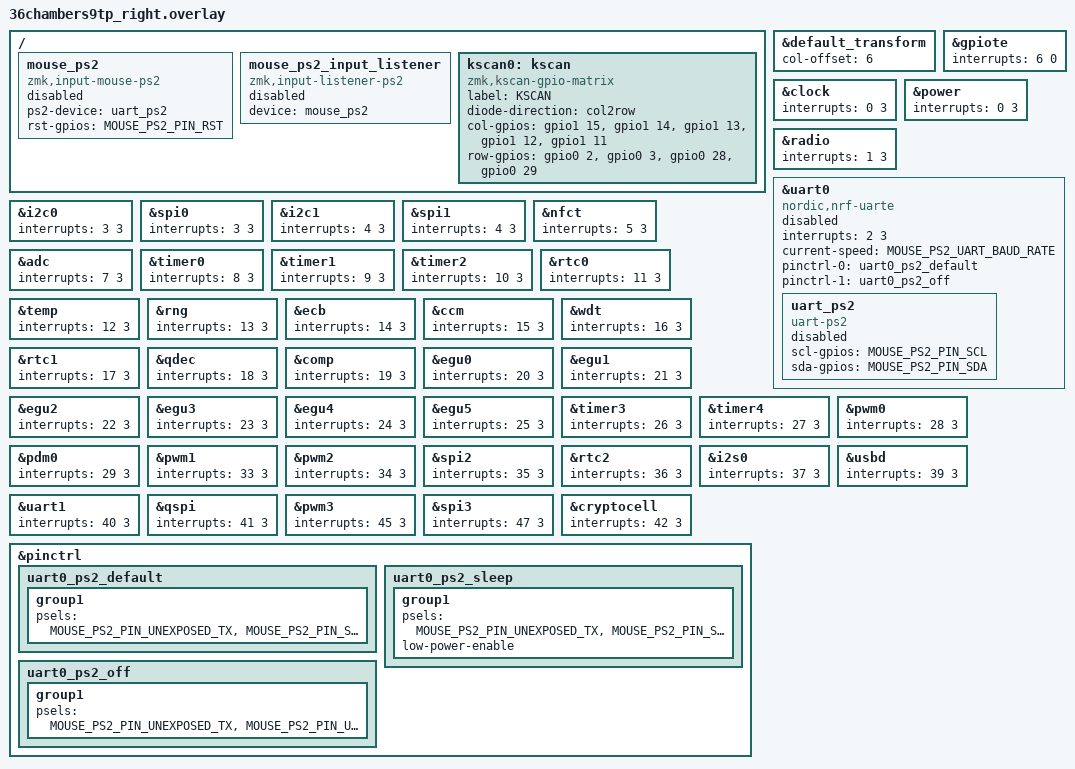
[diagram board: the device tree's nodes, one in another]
#include "36chambers9tp.dtsi"
#include <dt-bindings/zmk/input_transform.h>
#include <input/processors.dtsi>
/*
 * Pin Reference (XIAO BLE Plus):
 * SDA D4:  P0.04   SCL D5:  P1.11   DR D13:  P1.01
 * SS  D16: P0.31   MOSI D19: P1.07  MISO D18: P1.05  SCK D17: P1.03
 * Encoder Right1: P0.09 (D14), P0.10 (D15) — repurposed for trackpoint
 * Encoder Right2: P0.15 (D11), P0.19 (D12) — available
 *
 * PS/2 TrackPoint UART pin assignments:
 *   SDA (data / UART RX): P0.04
 *   SCL (clock / GPIO):   P0.09
 *   RST (reset / GPIO):   P0.10
 *   Dummy UART TX:         P0.27 (internal, not exposed)
 *   Dummy UART RX (off):   P1.01 (unused back pad)
 */

&default_transform {
	col-offset = <6>;
};

/*
 * PS/2 TrackPoint via UART — Configuration
 */
#define MOUSE_PS2_DRIVER_UART

#define MOUSE_PS2_PIN_SCL <&gpio0 9 GPIO_ACTIVE_HIGH>
#define MOUSE_PS2_PIN_SDA <&gpio0 4 GPIO_ACTIVE_HIGH>
#define MOUSE_PS2_PIN_SDA_PINCTRL <NRF_PSEL(UART_RX, 0, 4)>
#define MOUSE_PS2_PIN_RST <&gpio0 10 GPIO_ACTIVE_HIGH>

#define MOUSE_PS2_UART_BAUD_RATE <14400>

#define MOUSE_PS2_PIN_UNEXPOSED_TX <NRF_PSEL(UART_TX, 0, 27)>
#define MOUSE_PS2_PIN_UNEXPOSED_RX <NRF_PSEL(UART_RX, 1, 1)>

/*
 * Interrupt priority overrides — gpiote at highest (0), all others demoted to 3
 */
&gpiote { interrupts = < 6 0 >; };
&clock { interrupts = < 0 3 >; };
&power { interrupts = < 0 3 >; };
&radio { interrupts = < 1 3 >; };
&uart0 { interrupts = < 2 3 >; };
&i2c0 { interrupts = < 3 3 >; };
&spi0 { interrupts = < 3 3 >; };
&i2c1 { interrupts = < 4 3 >; };
&spi1 { interrupts = < 4 3 >; };
&nfct { interrupts = < 5 3 >; };
&adc { interrupts = < 7 3 >; };
&timer0 { interrupts = < 8 3 >; };
&timer1 { interrupts = < 9 3 >; };
&timer2 { interrupts = < 10 3 >; };
&rtc0 { interrupts = < 11 3 >; };
&temp { interrupts = < 12 3 >; };
&rng { interrupts = < 13 3 >; };
&ecb { interrupts = < 14 3 >; };
&ccm { interrupts = < 15 3 >; };
&wdt { interrupts = < 16 3 >; };
&rtc1 { interrupts = < 17 3 >; };
&qdec { interrupts = < 18 3 >; };
&comp { interrupts = < 19 3 >; };
&egu0 { interrupts = < 20 3 >; };
&egu1 { interrupts = < 21 3 >; };
&egu2 { interrupts = < 22 3 >; };
&egu3 { interrupts = < 23 3 >; };
&egu4 { interrupts = < 24 3 >; };
&egu5 { interrupts = < 25 3 >; };
&timer3 { interrupts = < 26 3 >; };
&timer4 { interrupts = < 27 3 >; };
&pwm0 { interrupts = < 28 3 >; };
&pdm0 { interrupts = < 29 3 >; };
&pwm1 { interrupts = < 33 3 >; };
&pwm2 { interrupts = < 34 3 >; };
&spi2 { interrupts = < 35 3 >; };
&rtc2 { interrupts = < 36 3 >; };
&i2s0 { interrupts = < 37 3 >; };
&usbd { interrupts = < 39 3 >; };
&uart1 { interrupts = < 40 3 >; };
&qspi { interrupts = < 41 3 >; };
&pwm3 { interrupts = < 45 3 >; };
&spi3 { interrupts = < 47 3 >; };
&cryptocell { interrupts = < 42 3 >; };

/*
 * Pinctrl — UART0 states for PS/2
 */
&pinctrl {
	uart0_ps2_default: uart0_ps2_default {
		group1 {
			psels = MOUSE_PS2_PIN_UNEXPOSED_TX,
					MOUSE_PS2_PIN_SDA_PINCTRL;
		};
	};
	uart0_ps2_sleep: uart0_ps2_sleep {
		group1 {
			psels = MOUSE_PS2_PIN_UNEXPOSED_TX,
					MOUSE_PS2_PIN_SDA_PINCTRL;
			low-power-enable;
		};
	};
	uart0_ps2_off: uart0_ps2_off {
		group1 {
			psels = MOUSE_PS2_PIN_UNEXPOSED_TX,
					MOUSE_PS2_PIN_UNEXPOSED_RX;
		};
	};
};

/*
 * UART0 — reconfigured for PS/2
 */
&uart0 {
    status = "disabled";
    compatible = "nordic,nrf-uarte";
    current-speed = MOUSE_PS2_UART_BAUD_RATE;
    pinctrl-0 = <&uart0_ps2_default>;
    pinctrl-1 = <&uart0_ps2_off>;
    pinctrl-names = "default", "sleep";

    uart_ps2: uart_ps2 {
        status = "disabled";
        compatible = "uart-ps2";
        scl-gpios = MOUSE_PS2_PIN_SCL;
        sda-gpios = MOUSE_PS2_PIN_SDA;
    };
};

/*
 * PS/2 Mouse input device and listener
 */
/ {
    mouse_ps2: mouse_ps2 {
        status = "disabled";
        compatible = "zmk,input-mouse-ps2";
        ps2-device = <&uart_ps2>;
        rst-gpios = MOUSE_PS2_PIN_RST;
    };

    mouse_ps2_input_listener: mouse_ps2_input_listener {
        compatible = "zmk,input-listener-ps2";
        status = "disabled";
        device = <&mouse_ps2>;
    };
};

/*
 * Keyboard matrix (right half)
 */
/ {
    kscan0: kscan {
        compatible = "zmk,kscan-gpio-matrix";
        label = "KSCAN";
        diode-direction = "col2row";
    col-gpios
    	= <&gpio1 15 GPIO_ACTIVE_HIGH>//Col0
        , <&gpio1 14 GPIO_ACTIVE_HIGH>//Col1
        , <&gpio1 13 GPIO_ACTIVE_HIGH>//Col2
        , <&gpio1 12 GPIO_ACTIVE_HIGH>//Col3
        , <&gpio1 11 GPIO_ACTIVE_HIGH>//Col4
        ;
	row-gpios
        = <&gpio0 2 (GPIO_ACTIVE_HIGH | GPIO_PULL_DOWN)>   //Row2
        , <&gpio0 3 (GPIO_ACTIVE_HIGH | GPIO_PULL_DOWN)>   //Row3
        , <&gpio0 28 (GPIO_ACTIVE_HIGH | GPIO_PULL_DOWN)>  //Row0
        , <&gpio0 29 (GPIO_ACTIVE_HIGH | GPIO_PULL_DOWN)>   //Row1
        ;
    };
};

// Build: west build -d build/369tpright -p -b xiao_ble -- -DSHIELD=36chambers9tp_right -DZMK_EXTRA_MODULES="/workspaces/zmk/app/kb_zmk_ps2_mouse_trackpoint_driver-main"

